# LM3S5752 register map
File version: 7944
Registers are 32-bit, read-write, no defined reset value unless marked. A register's access mark holds for its fields unless they carry their own. Offsets are from the block's base; [hi:lo] are bit positions; {n}, {i} and the like mark numbered series.

## COMP — Register map for COMP peripheral
Base 0x4003C000; register names take the prefix COMP
0x00 ACMIS — Analog Comparator Masked Interrupt Status
  [0] COMP_ACMIS_IN0 — Comparator 0 Masked Interrupt Status
0x04 ACRIS — Analog Comparator Raw Interrupt Status
  [0] COMP_ACRIS_IN0 — Comparator 0 Interrupt Status
0x08 ACINTEN — Analog Comparator Interrupt Enable
  [0] COMP_ACINTEN_IN0 — Comparator 0 Interrupt Enable
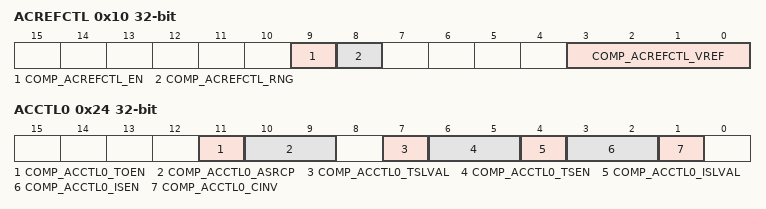
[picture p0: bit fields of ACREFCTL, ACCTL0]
0x10 ACREFCTL — Analog Comparator Reference Voltage Control
  [9] COMP_ACREFCTL_EN — Resistor Ladder Enable
  [8] COMP_ACREFCTL_RNG — Resistor Ladder Range
  [3:0] COMP_ACREFCTL_VREF — Resistor Ladder Voltage Ref
0x20 ACSTAT0 — Analog Comparator Status 0
  [1] COMP_ACSTAT0_OVAL — Comparator Output Value
0x24 ACCTL0 — Analog Comparator Control 0
  [11] COMP_ACCTL0_TOEN — Trigger Output Enable
  [10:9] COMP_ACCTL0_ASRCP — Analog Source Positive
    0=COMP_ACCTL0_ASRCP_PIN (Pin value of Cn+); 1=COMP_ACCTL0_ASRCP_PIN0 (Pin value of C0+); 2=COMP_ACCTL0_ASRCP_REF (Internal voltage reference (VIREF))
  [7] COMP_ACCTL0_TSLVAL — Trigger Sense Level Value
  [6:5] COMP_ACCTL0_TSEN — Trigger Sense
    0=COMP_ACCTL0_TSEN_LEVEL (Level sense, see TSLVAL); 1=COMP_ACCTL0_TSEN_FALL (Falling edge); 2=COMP_ACCTL0_TSEN_RISE (Rising edge); 3=COMP_ACCTL0_TSEN_BOTH (Either edge)
  [4] COMP_ACCTL0_ISLVAL — Interrupt Sense Level Value
  [3:2] COMP_ACCTL0_ISEN — Interrupt Sense
    0=COMP_ACCTL0_ISEN_LEVEL (Level sense, see ISLVAL); 1=COMP_ACCTL0_ISEN_FALL (Falling edge); 2=COMP_ACCTL0_ISEN_RISE (Rising edge); 3=COMP_ACCTL0_ISEN_BOTH (Either edge)
  [1] COMP_ACCTL0_CINV — Comparator Output Invert

## HIB — Register map for HIB peripheral
Base 0x400FC000; register names take the prefix HIB
0x00 RTCC — Hibernation RTC Counter
  [31:0] HIB_RTCC — RTC Counter
0x04 RTCM0 — Hibernation RTC Match 0
  [31:0] HIB_RTCM0 — RTC Match 0
0x08 RTCM1 — Hibernation RTC Match 1
  [31:0] HIB_RTCM1 — RTC Match 1
0x0C RTCLD — Hibernation RTC Load
  [31:0] HIB_RTCLD — RTC Load
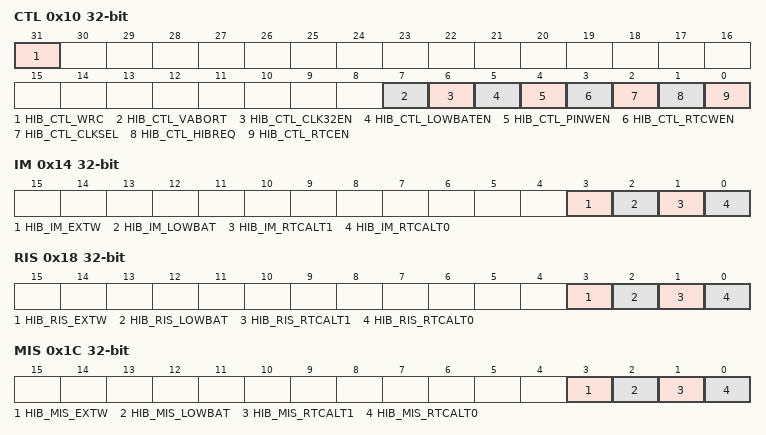
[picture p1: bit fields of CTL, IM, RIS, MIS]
0x10 CTL — Hibernation Control
  [31] HIB_CTL_WRC — Write Complete/Capable
  [7] HIB_CTL_VABORT — Power Cut Abort Enable
  [6] HIB_CTL_CLK32EN — Clocking Enable
  [5] HIB_CTL_LOWBATEN — Low Battery Monitoring Enable
  [4] HIB_CTL_PINWEN — External WAKE Pin Enable
  [3] HIB_CTL_RTCWEN — RTC Wake-up Enable
  [2] HIB_CTL_CLKSEL — Hibernation Module Clock Select
  [1] HIB_CTL_HIBREQ — Hibernation Request
  [0] HIB_CTL_RTCEN — RTC Timer Enable
0x14 IM — Hibernation Interrupt Mask
  [3] HIB_IM_EXTW — External Wake-Up Interrupt Mask
  [2] HIB_IM_LOWBAT — Low Battery Voltage Interrupt Mask
  [1] HIB_IM_RTCALT1 — RTC Alert 1 Interrupt Mask
  [0] HIB_IM_RTCALT0 — RTC Alert 0 Interrupt Mask
0x18 RIS — Hibernation Raw Interrupt Status
  [3] HIB_RIS_EXTW — External Wake-Up Raw Interrupt Status
  [2] HIB_RIS_LOWBAT — Low Battery Voltage Raw Interrupt Status
  [1] HIB_RIS_RTCALT1 — RTC Alert 1 Raw Interrupt Status
  [0] HIB_RIS_RTCALT0 — RTC Alert 0 Raw Interrupt Status
0x1C MIS — Hibernation Masked Interrupt Status
  [3] HIB_MIS_EXTW — External Wake-Up Masked Interrupt Status
  [2] HIB_MIS_LOWBAT — Low Battery Voltage Masked Interrupt Status
  [1] HIB_MIS_RTCALT1 — RTC Alert 1 Masked Interrupt Status
  [0] HIB_MIS_RTCALT0 — RTC Alert 0 Masked Interrupt Status
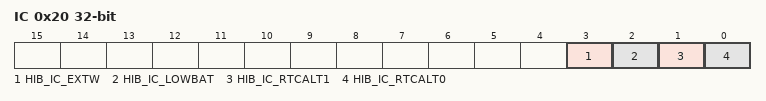
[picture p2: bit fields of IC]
0x20 IC — Hibernation Interrupt Clear
  [3] HIB_IC_EXTW — External Wake-Up Masked Interrupt Clear
  [2] HIB_IC_LOWBAT — Low Battery Voltage Masked Interrupt Clear
  [1] HIB_IC_RTCALT1 — RTC Alert1 Masked Interrupt Clear
  [0] HIB_IC_RTCALT0 — RTC Alert0 Masked Interrupt Clear
0x24 RTCT — Hibernation RTC Trim
  [15:0] HIB_RTCT_TRIM — RTC Trim Value
0x30 DATA — Hibernation Data
  [31:0] HIB_DATA_RTD — Hibernation Module NV Data

## FLASH_CTRL — Register map for FLASH_CTRL peripheral
Base 0x400FD000; register names take the prefix FLASH_CTRL
0x00 FMA — Flash Memory Address
  [16:0] FLASH_FMA_OFFSET — Address Offset
0x04 FMD — Flash Memory Data
  [31:0] FLASH_FMD_DATA — Data Value
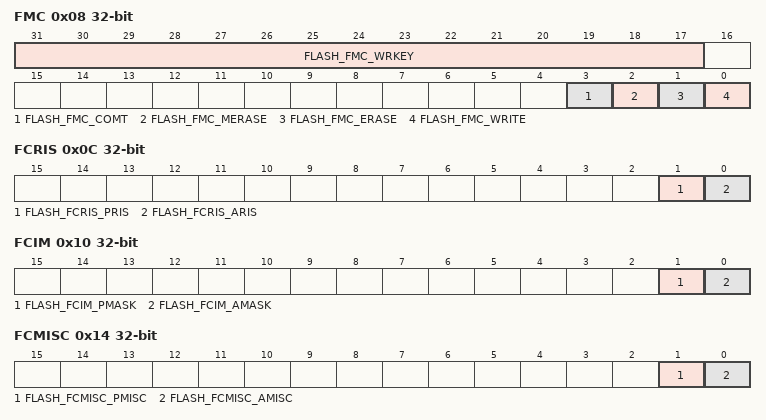
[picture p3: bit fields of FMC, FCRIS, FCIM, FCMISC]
0x08 FMC — Flash Memory Control
  [31:17] FLASH_FMC_WRKEY — FLASH write key
  [3] FLASH_FMC_COMT — Commit Register Value
  [2] FLASH_FMC_MERASE — Mass Erase Flash Memory
  [1] FLASH_FMC_ERASE — Erase a Page of Flash Memory
  [0] FLASH_FMC_WRITE — Write a Word into Flash Memory
0x0C FCRIS — Flash Controller Raw Interrupt Status
  [1] FLASH_FCRIS_PRIS — Programming Raw Interrupt Status
  [0] FLASH_FCRIS_ARIS — Access Raw Interrupt Status
0x10 FCIM — Flash Controller Interrupt Mask
  [1] FLASH_FCIM_PMASK — Programming Interrupt Mask
  [0] FLASH_FCIM_AMASK — Access Interrupt Mask
0x14 FCMISC — Flash Controller Masked Interrupt Status and Clear
  [1] FLASH_FCMISC_PMISC — Programming Masked Interrupt Status and Clear
  [0] FLASH_FCMISC_AMISC — Access Masked Interrupt Status and Clear
0x10F0 RMCTL — ROM Control
  [0] FLASH_RMCTL_BA — Boot Alias
0x1140 USECRL — USec Reload
  [7:0] FLASH_USECRL — Microsecond Reload Value
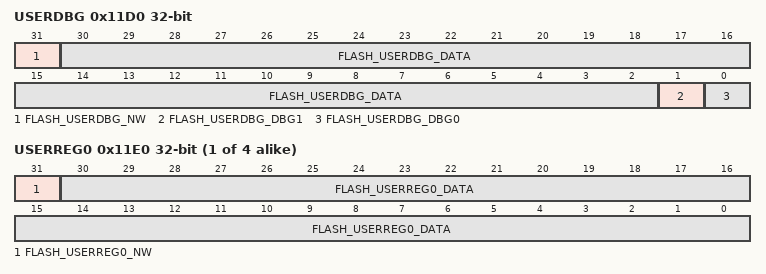
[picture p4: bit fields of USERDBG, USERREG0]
0x11D0 USERDBG (FLASH_ALT view) — User Debug
  [31] FLASH_USERDBG_NW — User Debug Not Written
  [30:2] FLASH_USERDBG_DATA — User Data
  [1] FLASH_USERDBG_DBG1 — Debug Control 1
  [0] FLASH_USERDBG_DBG0 — Debug Control 0
{0x11E0+4i} USERREG{i} (i=0..3) — User Register {i}
  [31] FLASH_USERREG{i}_NW — Not Written
  [30:0] FLASH_USERREG{i}_DATA — User Data
{0x1200+4i} FMPRE{i} (i=0..3) — Flash Memory Protection Read Enable {i}
{0x1400+4i} FMPPE{i} (i=0..3) — Flash Memory Protection Program Enable {i}

## UDMA — Register map for UDMA peripheral
Base 0x400FF000; register names take the prefix UDMA
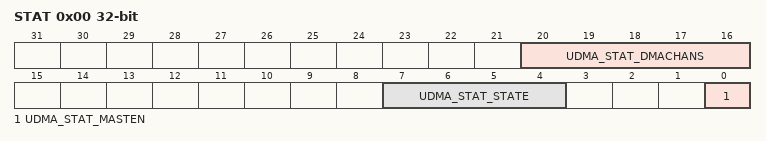
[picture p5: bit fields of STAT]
0x00 STAT — DMA Status
  [20:16] UDMA_STAT_DMACHANS — Available uDMA Channels Minus 1
  [7:4] UDMA_STAT_STATE — Control State Machine Status
    0=UDMA_STAT_STATE_IDLE (Idle); 1=UDMA_STAT_STATE_RD_CTRL (Reading channel controller data); 2=UDMA_STAT_STATE_RD_SRCENDP (Reading source end pointer); 3=UDMA_STAT_STATE_RD_DSTENDP (Reading destination end pointer); 4=UDMA_STAT_STATE_RD_SRCDAT (Reading source data); 5=UDMA_STAT_STATE_WR_DSTDAT (Writing destination data); 6=UDMA_STAT_STATE_WAIT (Waiting for uDMA request to clear); 7=UDMA_STAT_STATE_WR_CTRL (Writing channel controller data); 8=UDMA_STAT_STATE_STALL (Stalled); 9=UDMA_STAT_STATE_DONE (Done); 10=UDMA_STAT_STATE_UNDEF (Undefined)
  [0] UDMA_STAT_MASTEN — Master Enable Status
0x04 CFG wo — DMA Configuration
  [0] UDMA_CFG_MASTEN — Controller Master Enable
0x08 CTLBASE — DMA Channel Control Base Pointer
  [31:10] UDMA_CTLBASE_ADDR — Channel Control Base Address
0x0C ALTBASE — DMA Alternate Channel Control Base Pointer
  [31:0] UDMA_ALTBASE_ADDR — Alternate Channel Address Pointer
0x10 WAITSTAT — DMA Channel Wait-on-Request Status
  [31:0] UDMA_WAITSTAT_WAITREQ — Channel [n] Wait Status
0x14 SWREQ wo — DMA Channel Software Request
  [31:0] UDMA_SWREQ — Channel [n] Software Request
0x18 USEBURSTSET — DMA Channel Useburst Set
  [31:0] UDMA_USEBURSTSET_SET — Channel [n] Useburst Set
0x1C USEBURSTCLR wo — DMA Channel Useburst Clear
  [31:0] UDMA_USEBURSTCLR_CLR — Channel [n] Useburst Clear
0x20 REQMASKSET — DMA Channel Request Mask Set
  [31:0] UDMA_REQMASKSET_SET — Channel [n] Request Mask Set
0x24 REQMASKCLR wo — DMA Channel Request Mask Clear
  [31:0] UDMA_REQMASKCLR_CLR — Channel [n] Request Mask Clear
0x28 ENASET — DMA Channel Enable Set
  [31:0] UDMA_ENASET_SET — Channel [n] Enable Set
0x2C ENACLR wo — DMA Channel Enable Clear
  [31:0] UDMA_ENACLR_CLR — Clear Channel [n] Enable Clear
0x30 ALTSET — DMA Channel Primary Alternate Set
  [31:0] UDMA_ALTSET_SET — Channel [n] Alternate Set
0x34 ALTCLR wo — DMA Channel Primary Alternate Clear
  [31:0] UDMA_ALTCLR_CLR — Channel [n] Alternate Clear
0x38 PRIOSET — DMA Channel Priority Set
  [31:0] UDMA_PRIOSET_SET — Channel [n] Priority Set
0x3C PRIOCLR wo — DMA Channel Priority Clear
  [31:0] UDMA_PRIOCLR_CLR — Channel [n] Priority Clear
0x4C ERRCLR — DMA Bus Error Clear
  [0] UDMA_ERRCLR_ERRCLR — uDMA Bus Error Status
